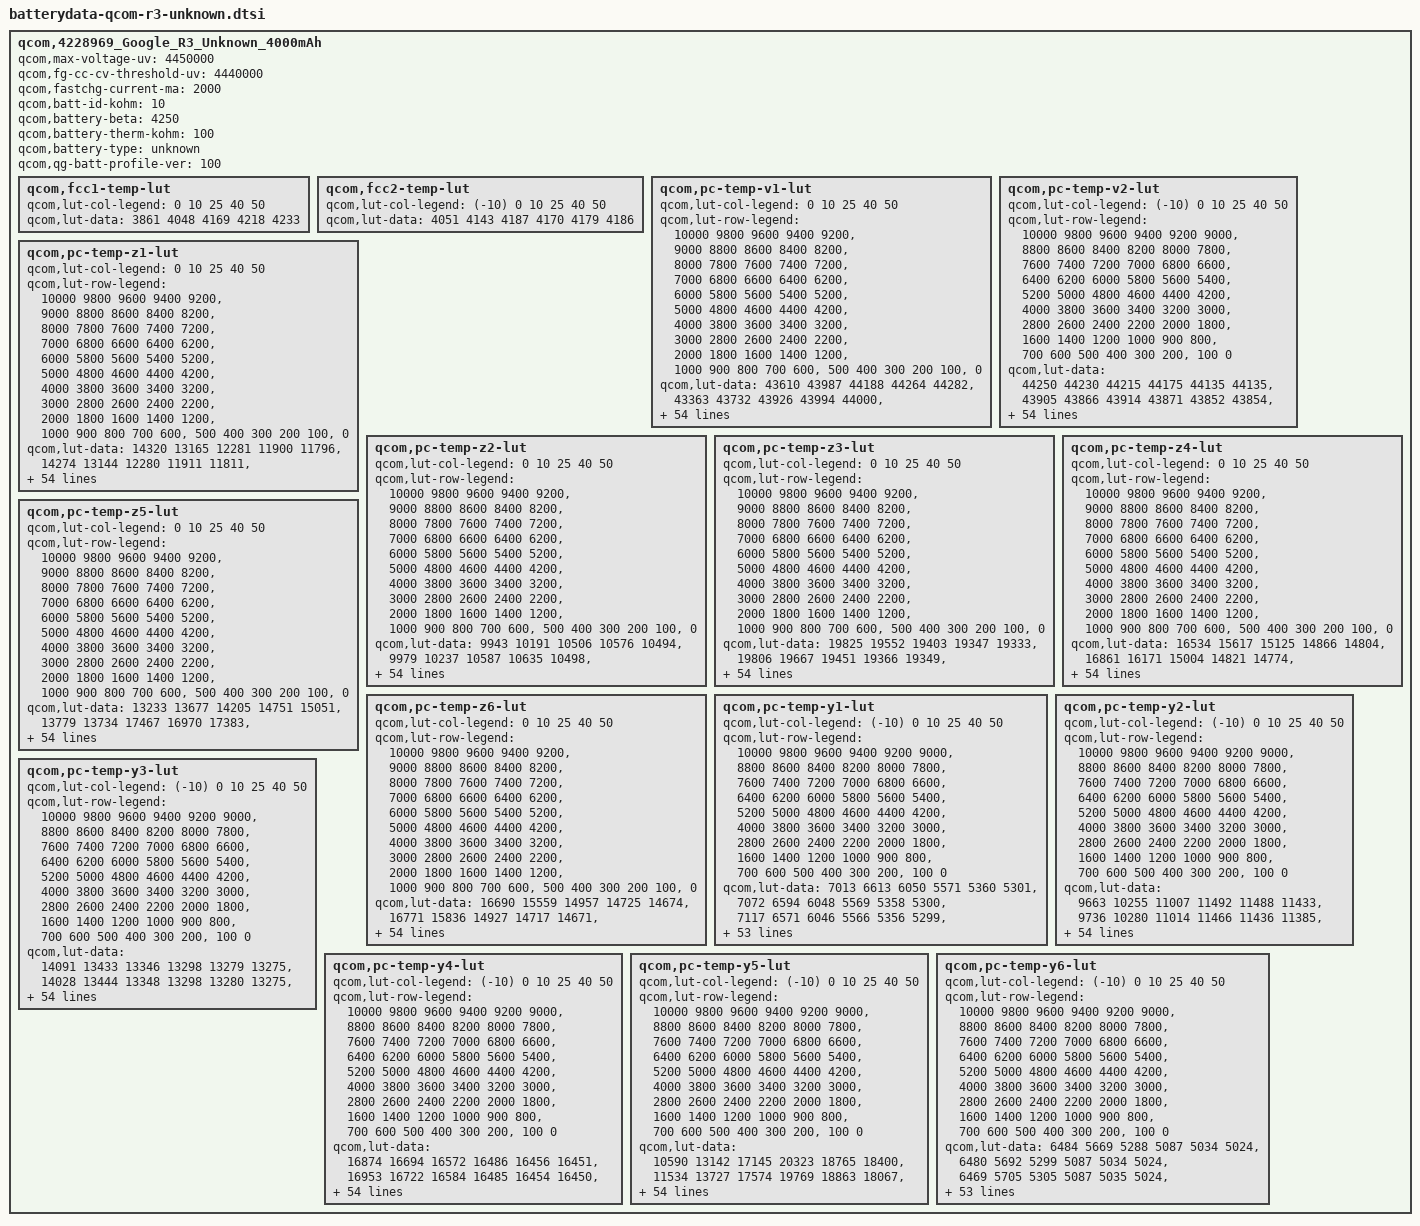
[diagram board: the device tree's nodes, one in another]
// SPDX-License-Identifier: GPL-2.0
qcom,4228969_Google_R3_Unknown_4000mAh {
	/* 4228969_Google_R3_LSN_4000mAh_Jan22nd2020 */
	qcom,max-voltage-uv = <4450000>;
	qcom,fg-cc-cv-threshold-uv = <4440000>;
	qcom,fastchg-current-ma = <2000>;
	qcom,batt-id-kohm = <10>;
	qcom,battery-beta = <4250>;
	qcom,battery-therm-kohm = <100>;
	qcom,battery-type = "unknown";
	qcom,qg-batt-profile-ver = <100>;

	qcom,fcc1-temp-lut {
		qcom,lut-col-legend = <0 10 25 40 50>;
		qcom,lut-data = <3861 4048 4169 4218 4233>;
	};

	qcom,fcc2-temp-lut {
		qcom,lut-col-legend = <(-10) 0 10 25 40 50>;
		qcom,lut-data = <4051 4143 4187 4170 4179 4186>;
	};

	qcom,pc-temp-v1-lut {
		qcom,lut-col-legend = <0 10 25 40 50>;
		qcom,lut-row-legend = <10000 9800 9600 9400 9200>,
			<9000 8800 8600 8400 8200>,
			<8000 7800 7600 7400 7200>,
			<7000 6800 6600 6400 6200>,
			<6000 5800 5600 5400 5200>,
			<5000 4800 4600 4400 4200>,
			<4000 3800 3600 3400 3200>,
			<3000 2800 2600 2400 2200>,
			<2000 1800 1600 1400 1200>,
			<1000 900 800 700 600>,
			<500 400 300 200 100>,
			<0>;
		qcom,lut-data = <43610 43987 44188 44264 44282>,
			<43363 43732 43926 43994 44000>,
			<43108 43494 43698 43755 43762>,
			<42851 43260 43463 43534 43538>,
			<42603 43015 43225 43300 43313>,
			<42361 42766 42981 43060 43081>,
			<42126 42519 42731 42816 42841>,
			<41895 42275 42482 42570 42596>,
			<41670 42034 42235 42323 42350>,
			<41451 41798 41991 42077 42103>,
			<41236 41567 41751 41835 41860>,
			<41027 41342 41514 41596 41620>,
			<40825 41123 41287 41363 41385>,
			<40628 40912 41069 41139 41159>,
			<40437 40709 40858 40924 40941>,
			<40252 40514 40655 40717 40732>,
			<40073 40326 40458 40518 40531>,
			<39905 40144 40271 40327 40339>,
			<39745 39969 40091 40143 40154>,
			<39594 39804 39918 39965 39975>,
			<39449 39646 39761 39795 39801>,
			<39311 39492 39595 39627 39630>,
			<39184 39343 39371 39427 39437>,
			<39064 39193 39104 39173 39197>,
			<38953 39040 38911 38961 38983>,
			<38852 38887 38778 38827 38838>,
			<38759 38734 38669 38717 38719>,
			<38675 38583 38574 38609 38606>,
			<38599 38473 38491 38506 38500>,
			<38529 38399 38413 38411 38404>,
			<38466 38341 38341 38325 38316>,
			<38409 38289 38274 38248 38237>,
			<38357 38242 38215 38180 38166>,
			<38309 38203 38161 38118 38101>,
			<38266 38171 38114 38064 38039>,
			<38222 38138 38072 38015 37980>,
			<38181 38103 38028 37963 37918>,
			<38137 38065 37985 37909 37852>,
			<38084 38013 37932 37846 37779>,
			<38023 37931 37848 37764 37692>,
			<37946 37829 37738 37661 37592>,
			<37834 37712 37622 37547 37479>,
			<37700 37575 37492 37414 37350>,
			<37537 37415 37338 37263 37200>,
			<37379 37266 37185 37111 37049>,
			<37245 37159 37081 37014 36956>,
			<37196 37120 37050 36988 36930>,
			<37154 37090 37032 36969 36911>,
			<37116 37059 37012 36950 36894>,
			<37061 37014 36970 36905 36843>,
			<36914 36828 36764 36684 36605>,
			<36523 36407 36346 36261 36176>,
			<35960 35830 35780 35698 35614>,
			<35185 35040 35010 34934 34849>,
			<33870 33737 33826 33768 33680>,
			<30000 30000 30000 30000 30000>;
	};

	qcom,pc-temp-v2-lut {
		qcom,lut-col-legend = <(-10) 0 10 25 40 50>;
		qcom,lut-row-legend = <10000 9800 9600 9400 9200 9000>,
			<8800 8600 8400 8200 8000 7800>,
			<7600 7400 7200 7000 6800 6600>,
			<6400 6200 6000 5800 5600 5400>,
			<5200 5000 4800 4600 4400 4200>,
			<4000 3800 3600 3400 3200 3000>,
			<2800 2600 2400 2200 2000 1800>,
			<1600 1400 1200 1000 900 800>,
			<700 600 500 400 300 200>,
			<100 0>;
		qcom,lut-data = <44250 44230 44215 44175 44135 44135>,
			<43905 43866 43914 43871 43852 43854>,
			<43590 43541 43635 43590 43586 43588>,
			<43308 43263 43380 43333 43337 43341>,
			<43057 43023 43148 43100 43106 43111>,
			<42811 42782 42910 42863 42871 42877>,
			<42558 42529 42660 42616 42626 42634>,
			<42308 42275 42409 42369 42381 42390>,
			<42062 42026 42161 42123 42137 42148>,
			<41819 41779 41914 41879 41893 41906>,
			<41576 41534 41673 41639 41655 41669>,
			<41330 41291 41437 41403 41420 41433>,
			<41082 41053 41206 41174 41191 41204>,
			<40837 40826 40978 40953 40968 40982>,
			<40591 40604 40753 40739 40753 40766>,
			<40346 40378 40530 40534 40548 40560>,
			<40089 40149 40308 40337 40352 40362>,
			<39842 39926 40085 40146 40164 40172>,
			<39625 39710 39857 39967 39987 39993>,
			<39425 39502 39637 39782 39808 39813>,
			<39236 39309 39434 39567 39610 39625>,
			<39054 39127 39243 39333 39402 39431>,
			<38883 38953 39068 39125 39192 39224>,
			<38720 38786 38905 38935 38977 38997>,
			<38566 38629 38754 38770 38795 38809>,
			<38430 38481 38615 38634 38657 38670>,
			<38307 38343 38487 38515 38540 38551>,
			<38202 38217 38372 38405 38432 38442>,
			<38119 38099 38266 38304 38333 38341>,
			<38048 38005 38165 38212 38242 38248>,
			<37981 37942 38068 38130 38159 38162>,
			<37916 37889 37978 38054 38084 38083>,
			<37854 37838 37899 37982 38016 38015>,
			<37791 37789 37828 37914 37951 37949>,
			<37731 37739 37771 37847 37880 37873>,
			<37667 37687 37725 37780 37802 37785>,
			<37601 37630 37678 37711 37715 37690>,
			<37533 37569 37627 37637 37615 37577>,
			<37463 37501 37569 37560 37513 37465>,
			<37391 37426 37496 37482 37427 37374>,
			<37315 37343 37408 37403 37347 37291>,
			<37234 37247 37314 37306 37254 37201>,
			<37145 37138 37200 37192 37145 37092>,
			<37045 37024 37056 37058 37022 36968>,
			<36934 36910 36908 36912 36875 36824>,
			<36810 36803 36814 36851 36830 36782>,
			<36733 36751 36778 36837 36820 36769>,
			<36648 36703 36741 36815 36802 36755>,
			<36537 36645 36690 36784 36777 36730>,
			<36389 36564 36609 36710 36710 36654>,
			<36162 36390 36404 36454 36446 36371>,
			<35823 36033 35966 35964 35970 35890>,
			<35310 35431 35317 35320 35340 35264>,
			<34482 34543 34375 34426 34473 34389>,
			<32998 32365 32901 33053 33195 33136>,
			<29620 29561 29514 29518 29529 29526>;
	};

	qcom,pc-temp-z1-lut {
		qcom,lut-col-legend = <0 10 25 40 50>;
		qcom,lut-row-legend = <10000 9800 9600 9400 9200>,
			<9000 8800 8600 8400 8200>,
			<8000 7800 7600 7400 7200>,
			<7000 6800 6600 6400 6200>,
			<6000 5800 5600 5400 5200>,
			<5000 4800 4600 4400 4200>,
			<4000 3800 3600 3400 3200>,
			<3000 2800 2600 2400 2200>,
			<2000 1800 1600 1400 1200>,
			<1000 900 800 700 600>,
			<500 400 300 200 100>,
			<0>;
		qcom,lut-data = <14320 13165 12281 11900 11796>,
			<14274 13144 12280 11911 11811>,
			<14258 13147 12276 11909 11810>,
			<14247 13151 12268 11901 11805>,
			<14228 13145 12261 11896 11803>,
			<14197 13134 12254 11893 11802>,
			<14164 13122 12242 11889 11801>,
			<14134 13110 12233 11886 11800>,
			<14103 13097 12227 11884 11799>,
			<14071 13080 12223 11882 11798>,
			<14021 13061 12218 11880 11798>,
			<13971 13046 12215 11879 11796>,
			<13943 13033 12214 11878 11795>,
			<13922 13026 12215 11877 11795>,
			<13901 13032 12216 11876 11795>,
			<13861 13043 12218 11875 11796>,
			<13815 13048 12220 11875 11796>,
			<13794 13051 12221 11875 11796>,
			<13780 13054 12221 11876 11796>,
			<13770 13072 12223 11877 11797>,
			<13761 13098 12228 11879 11798>,
			<13751 13108 12235 11881 11799>,
			<13748 13113 12237 11883 11800>,
			<13761 13117 12239 11885 11802>,
			<13772 13119 12242 11888 11805>,
			<13773 13120 12247 11891 11807>,
			<13774 13125 12253 11894 11810>,
			<13782 13132 12258 11897 11812>,
			<13832 13140 12263 11901 11815>,
			<13891 13153 12268 11904 11817>,
			<13894 13166 12274 11907 11820>,
			<13864 13173 12280 11910 11822>,
			<13843 13178 12285 11914 11825>,
			<13850 13186 12289 11917 11827>,
			<13868 13216 12295 11921 11830>,
			<13889 13246 12302 11925 11833>,
			<13919 13253 12309 11929 11836>,
			<13952 13260 12316 11934 11839>,
			<13980 13266 12323 11939 11842>,
			<14007 13272 12332 11942 11845>,
			<14044 13277 12340 11945 11847>,
			<14108 13298 12346 11948 11850>,
			<14135 13328 12350 11952 11852>,
			<14070 13307 12358 11955 11854>,
			<14043 13290 12365 11957 11855>,
			<14041 13271 12369 11961 11856>,
			<14115 13285 12369 11962 11857>,
			<14041 13297 12376 11963 11858>,
			<14098 13314 12375 11966 11860>,
			<14078 13300 12392 11972 11863>,
			<14049 13330 12397 11976 11867>,
			<14131 13355 12410 11985 11874>,
			<14078 13326 12433 11995 11882>,
			<14097 13366 12454 12014 11894>,
			<14097 13366 12454 12014 11894>,
			<14097 13366 12454 12014 11894>;
	};

	qcom,pc-temp-z2-lut {
		qcom,lut-col-legend = <0 10 25 40 50>;
		qcom,lut-row-legend = <10000 9800 9600 9400 9200>,
			<9000 8800 8600 8400 8200>,
			<8000 7800 7600 7400 7200>,
			<7000 6800 6600 6400 6200>,
			<6000 5800 5600 5400 5200>,
			<5000 4800 4600 4400 4200>,
			<4000 3800 3600 3400 3200>,
			<3000 2800 2600 2400 2200>,
			<2000 1800 1600 1400 1200>,
			<1000 900 800 700 600>,
			<500 400 300 200 100>,
			<0>;
		qcom,lut-data = <9943 10191 10506 10576 10494>,
			<9979 10237 10587 10635 10498>,
			<10006 10260 10582 10680 10546>,
			<10034 10271 10541 10671 10603>,
			<10054 10277 10503 10658 10555>,
			<10070 10283 10473 10639 10514>,
			<10079 10284 10442 10600 10510>,
			<10079 10279 10426 10560 10505>,
			<10078 10275 10426 10560 10483>,
			<10078 10271 10431 10577 10427>,
			<10080 10268 10442 10590 10401>,
			<10082 10264 10461 10606 10417>,
			<10084 10256 10479 10618 10441>,
			<10086 10252 10502 10602 10455>,
			<10088 10254 10527 10575 10469>,
			<10094 10259 10550 10565 10483>,
			<10100 10262 10571 10558 10499>,
			<10103 10261 10585 10557 10514>,
			<10104 10262 10597 10565 10527>,
			<10105 10269 10609 10575 10540>,
			<10105 10281 10625 10583 10557>,
			<10105 10292 10639 10591 10580>,
			<10103 10303 10642 10601 10596>,
			<10087 10314 10638 10612 10609>,
			<10066 10330 10629 10617 10626>,
			<10051 10347 10600 10641 10654>,
			<10036 10358 10582 10679 10683>,
			<10026 10367 10591 10695 10668>,
			<10021 10375 10610 10704 10589>,
			<10016 10382 10629 10702 10518>,
			<10010 10389 10653 10649 10460>,
			<9996 10396 10662 10606 10427>,
			<9973 10402 10658 10614 10436>,
			<9848 10410 10654 10632 10464>,
			<9672 10419 10658 10650 10502>,
			<9618 10430 10670 10672 10562>,
			<9611 10442 10680 10697 10613>,
			<9603 10454 10690 10730 10651>,
			<9560 10468 10700 10763 10680>,
			<9480 10486 10718 10791 10699>,
			<9434 10503 10736 10815 10713>,
			<9414 10516 10737 10824 10715>,
			<9410 10530 10731 10827 10713>,
			<9432 10550 10731 10809 10710>,
			<9355 10650 10749 10781 10707>,
			<9312 10760 10830 10779 10735>,
			<9327 10724 10830 10777 10729>,
			<9344 10742 10884 10763 10720>,
			<9354 10700 11021 10772 10751>,
			<9356 10702 11045 10853 10875>,
			<9368 10646 11002 10820 10698>,
			<9330 10525 10935 10717 10546>,
			<9299 10341 10923 10619 10472>,
			<9224 10132 10781 10560 10379>,
			<9224 10132 10781 10560 10379>,
			<9224 10132 10781 10560 10379>;
	};

	qcom,pc-temp-z3-lut {
		qcom,lut-col-legend = <0 10 25 40 50>;
		qcom,lut-row-legend = <10000 9800 9600 9400 9200>,
			<9000 8800 8600 8400 8200>,
			<8000 7800 7600 7400 7200>,
			<7000 6800 6600 6400 6200>,
			<6000 5800 5600 5400 5200>,
			<5000 4800 4600 4400 4200>,
			<4000 3800 3600 3400 3200>,
			<3000 2800 2600 2400 2200>,
			<2000 1800 1600 1400 1200>,
			<1000 900 800 700 600>,
			<500 400 300 200 100>,
			<0>;
		qcom,lut-data = <19825 19552 19403 19347 19333>,
			<19806 19667 19451 19366 19349>,
			<19821 19695 19479 19378 19349>,
			<19845 19704 19497 19401 19377>,
			<19852 19702 19500 19411 19378>,
			<19855 19695 19501 19415 19377>,
			<19856 19685 19500 19414 19378>,
			<19854 19667 19499 19412 19379>,
			<19850 19650 19489 19408 19378>,
			<19845 19632 19477 19398 19373>,
			<19838 19618 19470 19392 19368>,
			<19829 19612 19465 19389 19367>,
			<19818 19608 19458 19387 19365>,
			<19805 19604 19447 19379 19361>,
			<19791 19598 19439 19369 19356>,
			<19778 19589 19434 19364 19353>,
			<19764 19584 19431 19362 19350>,
			<19750 19582 19429 19360 19347>,
			<19735 19581 19428 19359 19345>,
			<19721 19580 19426 19358 19343>,
			<19708 19578 19425 19358 19342>,
			<19695 19578 19423 19357 19341>,
			<19683 19581 19431 19357 19340>,
			<19671 19585 19452 19359 19338>,
			<19658 19594 19457 19360 19336>,
			<19643 19605 19448 19356 19344>,
			<19627 19611 19439 19351 19358>,
			<19610 19615 19433 19357 19365>,
			<19594 19616 19428 19378 19372>,
			<19577 19612 19428 19386 19373>,
			<19559 19605 19430 19386 19368>,
			<19540 19601 19433 19386 19362>,
			<19519 19596 19436 19383 19356>,
			<19493 19591 19439 19379 19351>,
			<19466 19585 19439 19374 19347>,
			<19444 19579 19439 19370 19345>,
			<19429 19573 19439 19367 19343>,
			<19414 19566 19436 19365 19343>,
			<19390 19562 19432 19363 19342>,
			<19362 19560 19430 19361 19342>,
			<19353 19557 19429 19359 19342>,
			<19357 19550 19427 19359 19342>,
			<19363 19539 19425 19359 19339>,
			<19375 19530 19421 19358 19339>,
			<19322 19476 19411 19354 19339>,
			<19290 19347 19394 19345 19330>,
			<19286 19331 19392 19341 19327>,
			<19279 19304 19368 19340 19326>,
			<19279 19297 19341 19338 19321>,
			<19278 19295 19338 19333 19313>,
			<19277 19301 19340 19337 19331>,
			<19280 19305 19340 19340 19339>,
			<19282 19327 19329 19347 19340>,
			<19309 19350 19329 19344 19344>,
			<19309 19350 19329 19344 19344>,
			<19309 19350 19329 19344 19344>;
	};

	qcom,pc-temp-z4-lut {
		qcom,lut-col-legend = <0 10 25 40 50>;
		qcom,lut-row-legend = <10000 9800 9600 9400 9200>,
			<9000 8800 8600 8400 8200>,
			<8000 7800 7600 7400 7200>,
			<7000 6800 6600 6400 6200>,
			<6000 5800 5600 5400 5200>,
			<5000 4800 4600 4400 4200>,
			<4000 3800 3600 3400 3200>,
			<3000 2800 2600 2400 2200>,
			<2000 1800 1600 1400 1200>,
			<1000 900 800 700 600>,
			<500 400 300 200 100>,
			<0>;
		qcom,lut-data = <16534 15617 15125 14866 14804>,
			<16861 16171 15004 14821 14774>,
			<16669 15918 15075 14786 14745>,
			<16324 15630 15061 14859 14807>,
			<16070 15460 14956 14822 14791>,
			<15868 15328 14891 14784 14767>,
			<15701 15230 14847 14761 14747>,
			<15574 15154 14814 14743 14729>,
			<15470 15094 14788 14730 14719>,
			<15386 15046 14768 14722 14713>,
			<15316 15006 14754 14714 14708>,
			<15258 14966 14743 14706 14701>,
			<15214 14926 14737 14702 14696>,
			<15176 14894 14734 14702 14692>,
			<15149 14871 14731 14702 14689>,
			<15129 14853 14725 14701 14685>,
			<15113 14838 14717 14694 14679>,
			<15101 14824 14710 14687 14674>,
			<15089 14811 14704 14680 14668>,
			<15083 14797 14699 14676 14664>,
			<15083 14784 14694 14676 14665>,
			<15084 14773 14692 14677 14668>,
			<15087 14761 14715 14688 14679>,
			<15102 14756 14775 14756 14739>,
			<15121 14756 14799 14800 14785>,
			<15136 14758 14802 14796 14772>,
			<15152 14769 14803 14787 14744>,
			<15166 14801 14795 14768 14723>,
			<15180 14814 14780 14731 14704>,
			<15193 14809 14767 14708 14693>,
			<15206 14802 14752 14696 14687>,
			<15218 14795 14739 14689 14682>,
			<15233 14787 14728 14683 14676>,
			<15257 14778 14718 14680 14672>,
			<15284 14769 14712 14679 14671>,
			<15295 14760 14706 14679 14671>,
			<15300 14752 14703 14680 14672>,
			<15302 14744 14700 14682 14676>,
			<15295 14738 14699 14685 14682>,
			<15276 14733 14701 14688 14683>,
			<15249 14729 14706 14691 14684>,
			<15202 14726 14704 14690 14683>,
			<15147 14723 14693 14680 14676>,
			<15091 14716 14688 14679 14676>,
			<15035 14732 14681 14680 14677>,
			<15020 14819 14659 14659 14657>,
			<15018 14833 14653 14654 14652>,
			<15018 14856 14671 14641 14638>,
			<15011 14857 14688 14630 14628>,
			<15005 14853 14688 14631 14632>,
			<15007 14856 14700 14646 14635>,
			<15040 14879 14710 14651 14636>,
			<15078 14879 14729 14645 14637>,
			<15119 14887 14738 14650 14634>,
			<15119 14887 14738 14650 14634>,
			<15119 14887 14738 14650 14634>;
	};

	qcom,pc-temp-z5-lut {
		qcom,lut-col-legend = <0 10 25 40 50>;
		qcom,lut-row-legend = <10000 9800 9600 9400 9200>,
			<9000 8800 8600 8400 8200>,
			<8000 7800 7600 7400 7200>,
			<7000 6800 6600 6400 6200>,
			<6000 5800 5600 5400 5200>,
			<5000 4800 4600 4400 4200>,
			<4000 3800 3600 3400 3200>,
			<3000 2800 2600 2400 2200>,
			<2000 1800 1600 1400 1200>,
			<1000 900 800 700 600>,
			<500 400 300 200 100>,
			<0>;
		qcom,lut-data = <13233 13677 14205 14751 15051>,
			<13779 13734 17467 16970 17383>,
			<14764 14209 16788 19596 18856>,
			<15967 14802 16749 18016 19332>,
			<16988 15300 17504 19229 19263>,
			<17903 15764 18185 20345 19355>,
			<18714 16094 18847 20810 19805>,
			<19416 16337 19253 21106 20499>,
			<20033 16548 19431 21117 20776>,
			<20543 16718 19596 20923 20877>,
			<20996 16886 20053 20869 21024>,
			<21350 17231 20730 21305 21536>,
			<21585 17863 20865 21698 22037>,
			<21769 18334 20319 20991 21877>,
			<21834 18598 19885 19700 21436>,
			<21771 18788 20168 19508 21381>,
			<21645 18945 20864 19876 21793>,
			<21488 19311 21621 20384 22313>,
			<21239 19738 22541 21142 22912>,
			<20945 20344 23520 22035 23596>,
			<20648 21187 24351 23001 24209>,
			<20305 22231 25539 23943 24775>,
			<19849 23957 31829 24088 24656>,
			<19165 26503 44190 23475 21454>,
			<18417 31805 46892 22540 18520>,
			<17739 37987 38022 19871 18064>,
			<17078 41983 29632 17103 18245>,
			<16503 45242 26356 17548 19390>,
			<16020 46111 24325 20070 21823>,
			<15587 43439 24165 22429 23134>,
			<15179 39959 24731 24471 23830>,
			<14799 38276 25632 26354 24261>,
			<14409 37116 27676 28113 24601>,
			<13966 36002 30340 29671 25345>,
			<13520 34848 33077 30719 26365>,
			<13178 33855 35870 31550 28406>,
			<12934 33009 36694 31794 29347>,
			<12678 32271 36612 31300 29072>,
			<12239 32244 36440 30417 28569>,
			<11707 33887 35894 28798 27762>,
			<11508 35278 34975 26725 26533>,
			<11501 33644 34431 26480 25608>,
			<11534 30710 33837 27372 24929>,
			<11844 29611 32244 26637 24235>,
			<11734 24869 30080 24973 23667>,
			<11632 13803 28984 24662 23152>,
			<11609 13051 28639 23161 21824>,
			<11549 12285 21327 24821 24176>,
			<11490 12090 15899 26560 24855>,
			<11482 12073 15741 25483 21315>,
			<11480 12197 15528 21628 24090>,
			<11525 12051 14851 20058 24304>,
			<11391 12254 13743 21259 23245>,
			<11401 12377 13360 19464 23571>,
			<11401 12377 13360 19464 23571>,
			<11401 12377 13360 19464 23571>;
	};

	qcom,pc-temp-z6-lut {
		qcom,lut-col-legend = <0 10 25 40 50>;
		qcom,lut-row-legend = <10000 9800 9600 9400 9200>,
			<9000 8800 8600 8400 8200>,
			<8000 7800 7600 7400 7200>,
			<7000 6800 6600 6400 6200>,
			<6000 5800 5600 5400 5200>,
			<5000 4800 4600 4400 4200>,
			<4000 3800 3600 3400 3200>,
			<3000 2800 2600 2400 2200>,
			<2000 1800 1600 1400 1200>,
			<1000 900 800 700 600>,
			<500 400 300 200 100>,
			<0>;
		qcom,lut-data = <16690 15559 14957 14725 14674>,
			<16771 15836 14927 14717 14671>,
			<16672 15729 14967 14708 14658>,
			<16493 15600 14965 14749 14699>,
			<16359 15515 14920 14737 14692>,
			<16250 15443 14890 14724 14682>,
			<16157 15384 14869 14714 14675>,
			<16080 15335 14850 14705 14668>,
			<16015 15293 14831 14696 14662>,
			<15957 15255 14816 14687 14656>,
			<15905 15222 14805 14680 14651>,
			<15857 15194 14797 14676 14648>,
			<15813 15170 14790 14672 14644>,
			<15772 15152 14783 14667 14640>,
			<15737 15139 14777 14662 14636>,
			<15708 15129 14771 14658 14632>,
			<15683 15123 14766 14653 14628>,
			<15659 15118 14762 14650 14624>,
			<15634 15114 14759 14646 14621>,
			<15617 15112 14757 14644 14618>,
			<15605 15110 14755 14644 14618>,
			<15597 15109 14754 14644 14619>,
			<15596 15108 14769 14650 14623>,
			<15604 15108 14807 14681 14648>,
			<15615 15113 14819 14700 14668>,
			<15621 15123 14817 14697 14666>,
			<15626 15137 14815 14691 14663>,
			<15630 15155 14809 14687 14659>,
			<15636 15161 14802 14682 14655>,
			<15640 15160 14797 14678 14650>,
			<15642 15157 14793 14674 14645>,
			<15643 15154 14790 14670 14640>,
			<15643 15151 14787 14666 14635>,
			<15643 15148 14785 14663 14630>,
			<15642 15145 14784 14661 14628>,
			<15642 15143 14784 14659 14627>,
			<15643 15141 14783 14658 14627>,
			<15645 15140 14782 14659 14628>,
			<15651 15140 14782 14659 14630>,
			<15663 15141 14784 14660 14632>,
			<15674 15142 14787 14661 14633>,
			<15685 15141 14787 14661 14632>,
			<15689 15139 14783 14658 14628>,
			<15684 15136 14781 14657 14628>,
			<15648 15120 14776 14656 14629>,
			<15634 15100 14760 14643 14616>,
			<15637 15099 14758 14638 14612>,
			<15637 15097 14753 14633 14606>,
			<15635 15096 14749 14627 14598>,
			<15637 15100 14750 14626 14597>,
			<15648 15114 14760 14635 14608>,
			<15673 15136 14769 14641 14615>,
			<15703 15160 14778 14645 14618>,
			<15749 15197 14792 14650 14622>,
			<15749 15197 14792 14650 14622>,
			<15749 15197 14792 14650 14622>;
	};

	qcom,pc-temp-y1-lut {
		qcom,lut-col-legend = <(-10) 0 10 25 40 50>;
		qcom,lut-row-legend = <10000 9800 9600 9400 9200 9000>,
			<8800 8600 8400 8200 8000 7800>,
			<7600 7400 7200 7000 6800 6600>,
			<6400 6200 6000 5800 5600 5400>,
			<5200 5000 4800 4600 4400 4200>,
			<4000 3800 3600 3400 3200 3000>,
			<2800 2600 2400 2200 2000 1800>,
			<1600 1400 1200 1000 900 800>,
			<700 600 500 400 300 200>,
			<100 0>;
		qcom,lut-data = <7013 6613 6050 5571 5360 5301>,
			<7072 6594 6048 5569 5358 5300>,
			<7117 6571 6046 5566 5356 5299>,
			<7149 6549 6044 5563 5354 5298>,
			<7167 6532 6042 5560 5353 5298>,
			<7173 6526 6042 5558 5352 5297>,
			<7157 6525 6041 5554 5351 5296>,
			<7135 6526 6041 5551 5350 5295>,
			<7139 6534 6041 5551 5348 5294>,
			<7163 6547 6042 5550 5346 5294>,
			<7176 6552 6041 5549 5345 5293>,
			<7157 6548 6038 5546 5343 5291>,
			<7136 6546 6036 5544 5342 5290>,
			<7143 6557 6035 5543 5342 5290>,
			<7171 6574 6034 5543 5341 5290>,
			<7182 6572 6032 5544 5341 5290>,
			<7148 6546 6027 5544 5341 5290>,
			<7113 6533 6026 5544 5341 5291>,
			<7116 6543 6032 5545 5342 5291>,
			<7133 6554 6037 5546 5342 5291>,
			<7145 6552 6038 5547 5343 5291>,
			<7165 6541 6040 5548 5343 5292>,
			<7180 6539 6042 5550 5344 5292>,
			<7162 6551 6045 5553 5345 5293>,
			<7118 6560 6046 5556 5346 5294>,
			<7109 6556 6041 5558 5347 5295>,
			<7148 6550 6037 5559 5348 5296>,
			<7179 6554 6038 5562 5350 5297>,
			<7155 6569 6042 5566 5351 5298>,
			<7112 6578 6044 5568 5353 5299>,
			<7110 6575 6043 5570 5355 5300>,
			<7165 6570 6042 5572 5357 5301>,
			<7206 6565 6047 5575 5360 5302>,
			<7168 6557 6053 5579 5362 5304>,
			<7103 6550 6052 5581 5364 5306>,
			<7090 6538 6046 5581 5365 5308>,
			<7102 6528 6044 5582 5367 5309>,
			<7111 6536 6048 5585 5368 5309>,
			<7127 6555 6053 5589 5369 5310>,
			<7144 6559 6052 5593 5371 5311>,
			<7130 6549 6049 5599 5373 5312>,
			<7085 6541 6060 5598 5374 5314>,
			<7116 6537 6059 5603 5375 5315>,
			<7174 6556 6075 5606 5379 5316>,
			<7137 6601 6090 5613 5380 5319>,
			<7120 6588 6086 5615 5384 5321>,
			<7111 6582 6086 5618 5386 5322>,
			<7139 6567 6086 5628 5386 5322>,
			<7222 6577 6085 5624 5388 5323>,
			<7237 6584 6085 5633 5389 5323>,
			<7291 6628 6081 5629 5389 5324>,
			<7332 6656 6080 5645 5395 5328>,
			<7428 6729 6111 5658 5403 5334>,
			<7606 6876 6187 5676 5414 5342>,
			<7606 6876 6187 5676 5414 5342>,
			<7606 6876 6187 5676 5414 5342>;
	};

	qcom,pc-temp-y2-lut {
		qcom,lut-col-legend = <(-10) 0 10 25 40 50>;
		qcom,lut-row-legend = <10000 9800 9600 9400 9200 9000>,
			<8800 8600 8400 8200 8000 7800>,
			<7600 7400 7200 7000 6800 6600>,
			<6400 6200 6000 5800 5600 5400>,
			<5200 5000 4800 4600 4400 4200>,
			<4000 3800 3600 3400 3200 3000>,
			<2800 2600 2400 2200 2000 1800>,
			<1600 1400 1200 1000 900 800>,
			<700 600 500 400 300 200>,
			<100 0>;
		qcom,lut-data = <9663 10255 11007 11492 11488 11433>,
			<9736 10280 11014 11466 11436 11385>,
			<9807 10308 11010 11437 11378 11339>,
			<9872 10336 10998 11406 11324 11296>,
			<9929 10358 10981 11373 11281 11258>,
			<9974 10371 10960 11338 11257 11226>,
			<10008 10376 10930 11299 11245 11200>,
			<10036 10381 10898 11262 11240 11175>,
			<10064 10402 10875 11238 11244 11145>,
			<10090 10450 10857 11218 11252 11114>,
			<10116 10495 10854 11202 11246 11089>,
			<10145 10543 10862 11185 11230 11064>,
			<10172 10579 10874 11177 11211 11053>,
			<10166 10594 10909 11176 11181 11060>,
			<10085 10606 10954 11176 11152 11070>,
			<10027 10626 10981 11183 11162 11074>,
			<9868 10661 11002 11210 11211 11076>,
			<9707 10696 11019 11242 11267 11083>,
			<9691 10728 11030 11289 11329 11123>,
			<9686 10757 11044 11326 11392 11190>,
			<9683 10784 11070 11331 11455 11326>,
			<9679 10809 11105 11332 11511 11496>,
			<9676 10816 11130 11339 11506 11509>,
			<9674 10813 11149 11358 11425 11413>,
			<9673 10807 11162 11381 11379 11356>,
			<9672 10793 11171 11406 11400 11353>,
			<9671 10766 11179 11428 11433 11352>,
			<9670 10742 11189 11437 11452 11367>,
			<9669 10722 11198 11443 11472 11407>,
			<9668 10685 11200 11450 11485 11439>,
			<9667 10310 11189 11467 11506 11483>,
			<9667 9825 11177 11480 11534 11516>,
			<9666 9734 11169 11476 11572 11523>,
			<9665 9714 11162 11466 11609 11527>,
			<9664 9700 11147 11455 11611 11531>,
			<9664 9688 11118 11439 11592 11536>,
			<9663 9680 11084 11424 11568 11535>,
			<9663 9675 11050 11416 11526 11514>,
			<9663 9671 11008 11409 11476 11481>,
			<9662 9668 10947 11396 11446 11446>,
			<9662 9665 10868 11375 11430 11413>,
			<9661 9663 10794 11343 11425 11403>,
			<9661 9661 10721 11321 11419 11397>,
			<9661 9661 10566 11320 11426 11384>,
			<9660 9660 10332 11270 11454 11430>,
			<9660 9659 9998 11159 11366 11249>,
			<9659 9658 9864 11169 11309 11208>,
			<9659 9657 9759 11143 11284 11153>,
			<9658 9657 9706 11111 11293 11130>,
			<9656 9656 9682 11078 11309 11140>,
			<9654 9654 9669 11013 11233 11126>,
			<9653 9652 9661 10891 11141 11095>,
			<9651 9650 9654 10761 11080 10969>,
			<9653 9649 9651 10604 10988 10835>,
			<9653 9649 9651 10604 10988 10835>,
			<9653 9649 9651 10604 10988 10835>;
	};

	qcom,pc-temp-y3-lut {
		qcom,lut-col-legend = <(-10) 0 10 25 40 50>;
		qcom,lut-row-legend = <10000 9800 9600 9400 9200 9000>,
			<8800 8600 8400 8200 8000 7800>,
			<7600 7400 7200 7000 6800 6600>,
			<6400 6200 6000 5800 5600 5400>,
			<5200 5000 4800 4600 4400 4200>,
			<4000 3800 3600 3400 3200 3000>,
			<2800 2600 2400 2200 2000 1800>,
			<1600 1400 1200 1000 900 800>,
			<700 600 500 400 300 200>,
			<100 0>;
		qcom,lut-data = <14091 13433 13346 13298 13279 13275>,
			<14028 13444 13348 13298 13280 13275>,
			<13967 13456 13350 13298 13281 13275>,
			<13910 13469 13354 13299 13282 13276>,
			<13861 13479 13356 13299 13283 13276>,
			<13821 13484 13357 13299 13284 13277>,
			<13790 13487 13358 13300 13285 13277>,
			<13764 13488 13359 13300 13286 13278>,
			<13738 13487 13360 13300 13287 13280>,
			<13713 13481 13361 13300 13287 13283>,
			<13688 13475 13362 13300 13288 13284>,
			<13659 13466 13363 13300 13288 13285>,
			<13632 13458 13364 13301 13288 13285>,
			<13613 13454 13363 13303 13287 13285>,
			<13597 13451 13362 13306 13287 13285>,
			<13585 13447 13361 13308 13287 13285>,
			<13577 13441 13359 13309 13289 13284>,
			<13571 13433 13357 13310 13291 13284>,
			<13564 13425 13352 13312 13292 13285>,
			<13555 13416 13348 13313 13293 13286>,
			<13549 13409 13345 13311 13293 13287>,
			<13546 13404 13342 13307 13292 13287>,
			<13544 13398 13340 13303 13289 13286>,
			<13542 13391 13338 13299 13284 13281>,
			<13542 13385 13336 13297 13281 13278>,
			<13541 13383 13334 13296 13281 13278>,
			<13540 13381 13332 13296 13281 13278>,
			<13540 13376 13332 13296 13281 13277>,
			<13548 13360 13331 13296 13280 13277>,
			<13566 13352 13331 13296 13280 13277>,
			<13584 13358 13331 13297 13280 13276>,
			<13601 13370 13330 13298 13281 13275>,
			<13622 13384 13328 13298 13282 13276>,
			<13652 13401 13326 13298 13283 13277>,
			<13689 13420 13326 13298 13283 13277>,
			<13725 13441 13329 13298 13283 13277>,
			<13761 13465 13332 13298 13282 13277>,
			<13799 13497 13336 13297 13281 13276>,
			<13842 13538 13339 13296 13280 13276>,
			<13886 13585 13341 13296 13280 13276>,
			<13928 13645 13342 13297 13280 13276>,
			<13968 13707 13347 13297 13280 13277>,
			<14006 13771 13349 13297 13280 13277>,
			<14040 13816 13335 13293 13280 13277>,
			<14046 13821 13332 13291 13277 13274>,
			<14031 13975 13347 13292 13280 13277>,
			<14084 14056 13364 13300 13283 13279>,
			<14156 14159 13395 13301 13284 13282>,
			<14290 14259 13437 13306 13288 13284>,
			<14501 14429 13497 13310 13290 13285>,
			<14823 14793 13594 13309 13285 13282>,
			<15411 15671 13835 13311 13285 13281>,
			<16594 18478 14539 13323 13287 13285>,
			<20353 34371 16860 13342 13293 13287>,
			<20353 34371 16860 13342 13293 13287>,
			<20353 34371 16860 13342 13293 13287>;
	};

	qcom,pc-temp-y4-lut {
		qcom,lut-col-legend = <(-10) 0 10 25 40 50>;
		qcom,lut-row-legend = <10000 9800 9600 9400 9200 9000>,
			<8800 8600 8400 8200 8000 7800>,
			<7600 7400 7200 7000 6800 6600>,
			<6400 6200 6000 5800 5600 5400>,
			<5200 5000 4800 4600 4400 4200>,
			<4000 3800 3600 3400 3200 3000>,
			<2800 2600 2400 2200 2000 1800>,
			<1600 1400 1200 1000 900 800>,
			<700 600 500 400 300 200>,
			<100 0>;
		qcom,lut-data = <16874 16694 16572 16486 16456 16451>,
			<16953 16722 16584 16485 16454 16450>,
			<17047 16784 16608 16485 16453 16449>,
			<17137 16856 16636 16485 16452 16449>,
			<17204 16912 16657 16487 16452 16449>,
			<17228 16930 16663 16489 16452 16449>,
			<17217 16929 16663 16491 16452 16450>,
			<17196 16928 16663 16494 16453 16450>,
			<17180 16927 16664 16498 16454 16450>,
			<17164 16927 16666 16504 16457 16448>,
			<17148 16926 16670 16510 16460 16448>,
			<17129 16924 16676 16517 16465 16452>,
			<17110 16922 16682 16524 16471 16456>,
			<17094 16915 16688 16531 16479 16461>,
			<17073 16904 16692 16539 16488 16466>,
			<17064 16888 16691 16551 16496 16473>,
			<17049 16861 16686 16567 16504 16482>,
			<17028 16834 16677 16582 16514 16492>,
			<17007 16810 16657 16600 16535 16505>,
			<16978 16788 16634 16611 16551 16516>,
			<16949 16764 16617 16595 16549 16523>,
			<16920 16740 16601 16553 16541 16529>,
			<16891 16717 16587 16522 16526 16522>,
			<16862 16696 16575 16496 16484 16479>,
			<16835 16673 16566 16484 16461 16454>,
			<16827 16643 16560 16482 16458 16452>,
			<16826 16612 16556 16481 16457 16451>,
			<16826 16606 16553 16481 16459 16452>,
			<16828 16610 16551 16484 16464 16456>,
			<16834 16617 16546 16488 16470 16462>,
			<16841 16639 16537 16493 16476 16469>,
			<16850 16668 16529 16497 16483 16477>,
			<16860 16683 16525 16503 16492 16487>,
			<16867 16692 16523 16508 16501 16495>,
			<16874 16702 16524 16508 16502 16496>,
			<16882 16714 16532 16504 16497 16491>,
			<16894 16727 16542 16498 16490 16484>,
			<16907 16740 16554 16489 16473 16469>,
			<16923 16752 16566 16480 16457 16455>,
			<16941 16758 16575 16478 16456 16453>,
			<16955 16761 16582 16478 16457 16453>,
			<16967 16763 16588 16479 16458 16456>,
			<16974 16763 16584 16478 16458 16455>,
			<16977 16752 16560 16472 16452 16449>,
			<16927 16712 16566 16463 16438 16433>,
			<16846 16730 16593 16475 16443 16439>,
			<16859 16751 16611 16477 16449 16449>,
			<16882 16773 16635 16491 16463 16464>,
			<16954 16804 16671 16512 16484 16492>,
			<17061 16858 16718 16534 16500 16503>,
			<17225 16992 16750 16519 16467 16457>,
			<17549 17302 16772 16509 16452 16447>,
			<18508 18922 17017 16536 16456 16450>,
			<23958 42026 19277 16595 16476 16465>,
			<23958 42026 19277 16595 16476 16465>,
			<23958 42026 19277 16595 16476 16465>;
	};

	qcom,pc-temp-y5-lut {
		qcom,lut-col-legend = <(-10) 0 10 25 40 50>;
		qcom,lut-row-legend = <10000 9800 9600 9400 9200 9000>,
			<8800 8600 8400 8200 8000 7800>,
			<7600 7400 7200 7000 6800 6600>,
			<6400 6200 6000 5800 5600 5400>,
			<5200 5000 4800 4600 4400 4200>,
			<4000 3800 3600 3400 3200 3000>,
			<2800 2600 2400 2200 2000 1800>,
			<1600 1400 1200 1000 900 800>,
			<700 600 500 400 300 200>,
			<100 0>;
		qcom,lut-data = <10590 13142 17145 20323 18765 18400>,
			<11534 13727 17574 19769 18863 18067>,
			<12436 14285 17705 19197 18920 17691>,
			<13280 14801 17661 18623 18948 17324>,
			<14045 15261 17563 18062 18957 17021>,
			<14713 15652 17517 17527 18955 16827>,
			<15295 15993 17345 16999 18885 16677>,
			<15810 16275 17146 16487 18754 16591>,
			<16287 16487 17026 15980 18524 17460>,
			<16752 16660 16888 15487 18123 19279>,
			<16979 16802 16887 15107 17645 19622>,
			<17020 16898 17092 14761 17008 18969>,
			<17055 17033 17385 14601 16329 18204>,
			<17146 17539 17768 14769 15512 17563>,
			<17169 18358 18279 15121 14850 16899>,
			<17053 19000 19006 15462 14810 16084>,
			<15741 19586 19953 15850 14924 15156>,
			<14407 19899 20386 16503 15071 14867>,
			<14307 19972 20512 18281 15337 14941>,
			<14258 20035 20623 20343 15823 15101>,
			<14213 20352 20854 21930 18001 16809>,
			<14186 21008 21177 23249 21446 19758>,
			<14150 21221 21467 23251 21966 20416>,
			<14030 21027 21770 21588 20794 20396>,
			<13767 20795 21892 20471 19913 20295>,
			<13427 20941 21649 20379 19653 20088>,
			<12845 21256 21366 20330 19432 19779>,
			<12417 20403 21615 20301 18917 19257>,
			<12355 16574 22444 20263 18119 18410>,
			<12326 13890 22921 20355 17869 17651>,
			<12276 13224 23184 21390 18172 16870>,
			<12185 12862 23257 22642 18678 16466>,
			<12129 12884 22231 23257 19454 16755>,
			<12174 13104 20569 23717 20515 17422>,
			<12267 13224 20188 24286 21488 18323>,
			<12318 13318 20581 25073 22507 19736>,
			<12342 13441 20923 25461 22890 20684>,
			<12374 13565 21304 24802 22737 21168>,
			<12447 13679 21609 23822 22434 21457>,
			<12561 13709 21048 23230 21901 21327>,
			<12702 13792 20068 22535 21176 20900>,
			<12888 13728 20236 21842 20540 21050>,
			<13038 13399 20122 21510 20308 21236>,
			<13185 13115 17683 19662 21824 22132>,
			<13468 13254 14995 18465 19467 20689>,
			<13819 13443 14349 16859 19436 18995>,
			<13930 13269 14259 20194 20529 18127>,
			<14098 13408 14308 18847 18543 18518>,
			<13703 13423 14144 19038 18891 17867>,
			<13326 13453 14222 19238 18873 17336>,
			<12475 12585 14145 19103 18349 19086>,
			<11551 11157 13738 19732 20342 19751>,
			<10431 9733 12102 21678 21181 22793>,
			<9485 9052 9864 21714 25601 24019>,
			<9485 9052 9864 21714 25601 24019>,
			<9485 9052 9864 21714 25601 24019>;
	};

	qcom,pc-temp-y6-lut {
		qcom,lut-col-legend = <(-10) 0 10 25 40 50>;
		qcom,lut-row-legend = <10000 9800 9600 9400 9200 9000>,
			<8800 8600 8400 8200 8000 7800>,
			<7600 7400 7200 7000 6800 6600>,
			<6400 6200 6000 5800 5600 5400>,
			<5200 5000 4800 4600 4400 4200>,
			<4000 3800 3600 3400 3200 3000>,
			<2800 2600 2400 2200 2000 1800>,
			<1600 1400 1200 1000 900 800>,
			<700 600 500 400 300 200>,
			<100 0>;
		qcom,lut-data = <6484 5669 5288 5087 5034 5024>,
			<6480 5692 5299 5087 5034 5024>,
			<6469 5705 5305 5087 5035 5024>,
			<6454 5712 5309 5087 5035 5024>,
			<6434 5714 5310 5087 5036 5024>,
			<6411 5714 5309 5087 5036 5024>,
			<6383 5707 5306 5087 5037 5025>,
			<6352 5696 5301 5088 5038 5026>,
			<6325 5687 5298 5089 5039 5027>,
			<6301 5679 5295 5090 5040 5029>,
			<6278 5671 5293 5091 5041 5030>,
			<6254 5663 5292 5093 5042 5031>,
			<6232 5656 5291 5095 5044 5032>,
			<6211 5650 5290 5098 5046 5034>,
			<6190 5644 5289 5102 5048 5035>,
			<6170 5635 5287 5106 5051 5037>,
			<6147 5624 5284 5112 5054 5039>,
			<6126 5613 5278 5117 5058 5042>,
			<6113 5602 5269 5123 5065 5046>,
			<6103 5592 5259 5127 5070 5050>,
			<6094 5586 5252 5121 5069 5053>,
			<6087 5580 5245 5106 5066 5054>,
			<6082 5575 5241 5095 5060 5051>,
			<6077 5570 5237 5085 5044 5035>,
			<6073 5566 5234 5080 5035 5026>,
			<6072 5563 5232 5079 5035 5025>,
			<6076 5562 5231 5079 5034 5025>,
			<6083 5562 5232 5079 5035 5025>,
			<6094 5565 5233 5080 5036 5026>,
			<6112 5571 5234 5082 5038 5027>,
			<6130 5585 5233 5085 5040 5029>,
			<6150 5607 5233 5088 5043 5031>,
			<6173 5630 5234 5090 5046 5034>,
			<6199 5658 5236 5092 5049 5038>,
			<6229 5690 5240 5093 5050 5038>,
			<6261 5726 5248 5092 5049 5037>,
			<6295 5767 5259 5091 5047 5035>,
			<6330 5814 5273 5089 5041 5030>,
			<6368 5866 5289 5087 5036 5026>,
			<6408 5921 5304 5087 5036 5026>,
			<6444 5980 5320 5089 5036 5026>,
			<6479 6041 5343 5091 5037 5027>,
			<6515 6101 5361 5092 5037 5028>,
			<6546 6145 5340 5088 5036 5026>,
			<6551 6150 5365 5086 5030 5019>,
			<6533 6280 5425 5093 5034 5024>,
			<6578 6351 5464 5100 5038 5028>,
			<6648 6438 5518 5107 5043 5035>,
			<6811 6529 5587 5119 5052 5045>,
			<7047 6688 5682 5130 5058 5048>,
			<7397 7045 5812 5128 5045 5033>,
			<8009 7838 6056 5133 5041 5030>,
			<9271 10371 6737 5164 5046 5034>,
			<13649 27659 9122 5217 5057 5041>,
			<13649 27659 9122 5217 5057 5041>,
			<13649 27659 9122 5217 5057 5041>;
	};
};
